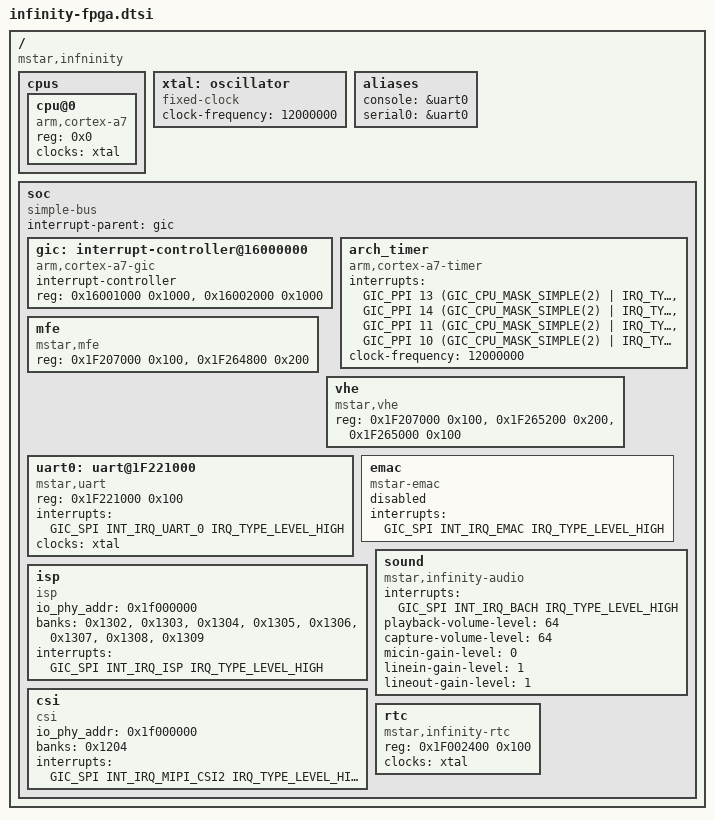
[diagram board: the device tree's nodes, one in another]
/*
 * Copyright (c) 2014 MundoReader S.L.
 * Author: Matthias Brugger <matthias.bgg@gmail.com>
 *
 * This program is free software; you can redistribute it and/or modify
 * it under the terms of the GNU General Public License as published by
 * the Free Software Foundation; either version 2 of the License, or
 * (at your option) any later version.
 *
 * This program is distributed in the hope that it will be useful,
 * but WITHOUT ANY WARRANTY; without even the implied warranty of
 * MERCHANTABILITY or FITNESS FOR A PARTICULAR PURPOSE.  See the
 * GNU General Public License for more details.
 */

#include <../../../../drivers/mstar/include/infinity/irqs.h>
#include <dt-bindings/interrupt-controller/irq.h>
#include <dt-bindings/interrupt-controller/arm-gic.h>
#include "skeleton.dtsi"

/ {
    compatible = "mstar,infninity";

    cpus {
        #address-cells = <1>;
        #size-cells = <0>;

        cpu@0 {
            device_type = "cpu";
            compatible = "arm,cortex-a7";
            reg = <0x0>;
            clocks = <&xtal>;
        };
    };

    xtal: oscillator {
        compatible = "fixed-clock";
        #clock-cells = <0>;
        clock-frequency = <12000000>;
    };

    aliases {
        console = &uart0;
        serial0 = &uart0;
    }; 

    soc {    
        compatible = "simple-bus";   
        interrupt-parent = <&gic>;
        #address-cells = <1>;
        #size-cells = <1>;
        ranges = <0 0 0xFFFFFFFF>;


        gic: interrupt-controller@16000000 {
            compatible = "arm,cortex-a7-gic";
            #interrupt-cells = <3>;
            #address-cells = <1>;
            #size-cells = <1>;
            interrupt-controller;
            reg = <0x16001000 0x1000>,
                  <0x16002000 0x1000>;
        };

        arch_timer {
            compatible = "arm,cortex-a7-timer", "arm,armv7-timer";
            interrupts = <GIC_PPI 13 (GIC_CPU_MASK_SIMPLE(2) | IRQ_TYPE_LEVEL_LOW)>,
                         <GIC_PPI 14 (GIC_CPU_MASK_SIMPLE(2) | IRQ_TYPE_LEVEL_LOW)>,
                         <GIC_PPI 11 (GIC_CPU_MASK_SIMPLE(2) | IRQ_TYPE_LEVEL_LOW)>,
                         <GIC_PPI 10 (GIC_CPU_MASK_SIMPLE(2) | IRQ_TYPE_LEVEL_LOW)>;
            clock-frequency = <12000000>;  /* arch_timer must use clock-frequency*/
        };

        mfe: mfe {
            compatible = "mstar,mfe";
			reg = <0x1F207000 0x100>,<0x1F264800 0x200>;
        };

        vhe: vhe {
            compatible = "mstar,vhe";
            reg = <0x1F207000 0x100>,<0x1F265200 0x200>,<0x1F265000 0x100>;
        };

        uart0: uart@1F221000 {
            compatible = "mstar,uart";
            reg = <0x1F221000 0x100>;
            interrupts= <GIC_SPI INT_IRQ_UART_0 IRQ_TYPE_LEVEL_HIGH>;
            status = "ok";
            clocks = <&xtal>;
        };

        emac {
            compatible = "mstar-emac";
            interrupts = <GIC_SPI INT_IRQ_EMAC IRQ_TYPE_LEVEL_HIGH>;
            status = "disabled";
        };

        isp: isp {
            compatible = "isp";
            io_phy_addr = <0x1f000000>;
            banks = <0x1302>,<0x1303>,<0x1304>,<0x1305>,<0x1306>,<0x1307>,<0x1308>,<0x1309>;
            interrupts=  <GIC_SPI INT_IRQ_ISP  IRQ_TYPE_LEVEL_HIGH>;
        };

        sound {
            compatible = "mstar,infinity-audio";
//            reg = <0x1F000000 0x1000000>;
            interrupts=<GIC_SPI INT_IRQ_BACH IRQ_TYPE_LEVEL_HIGH>;
            playback-volume-level=<64>;    //0~76
            capture-volume-level=<64>;
            micin-gain-level=<0>;    //0~5
            linein-gain-level=<1>;//0~6
            lineout-gain-level=<1>;//0~2
        };

        csi: csi {
            compatible = "csi";
            io_phy_addr = <0x1f000000>;
            banks = <0x1204>;
            interrupts=  <GIC_SPI INT_IRQ_MIPI_CSI2 IRQ_TYPE_LEVEL_HIGH>;
        };

        rtc {
            compatible = "mstar,infinity-rtc";
            reg = <0x1F002400 0x100>;
            clocks = <&xtal>;
        };
    };
};
